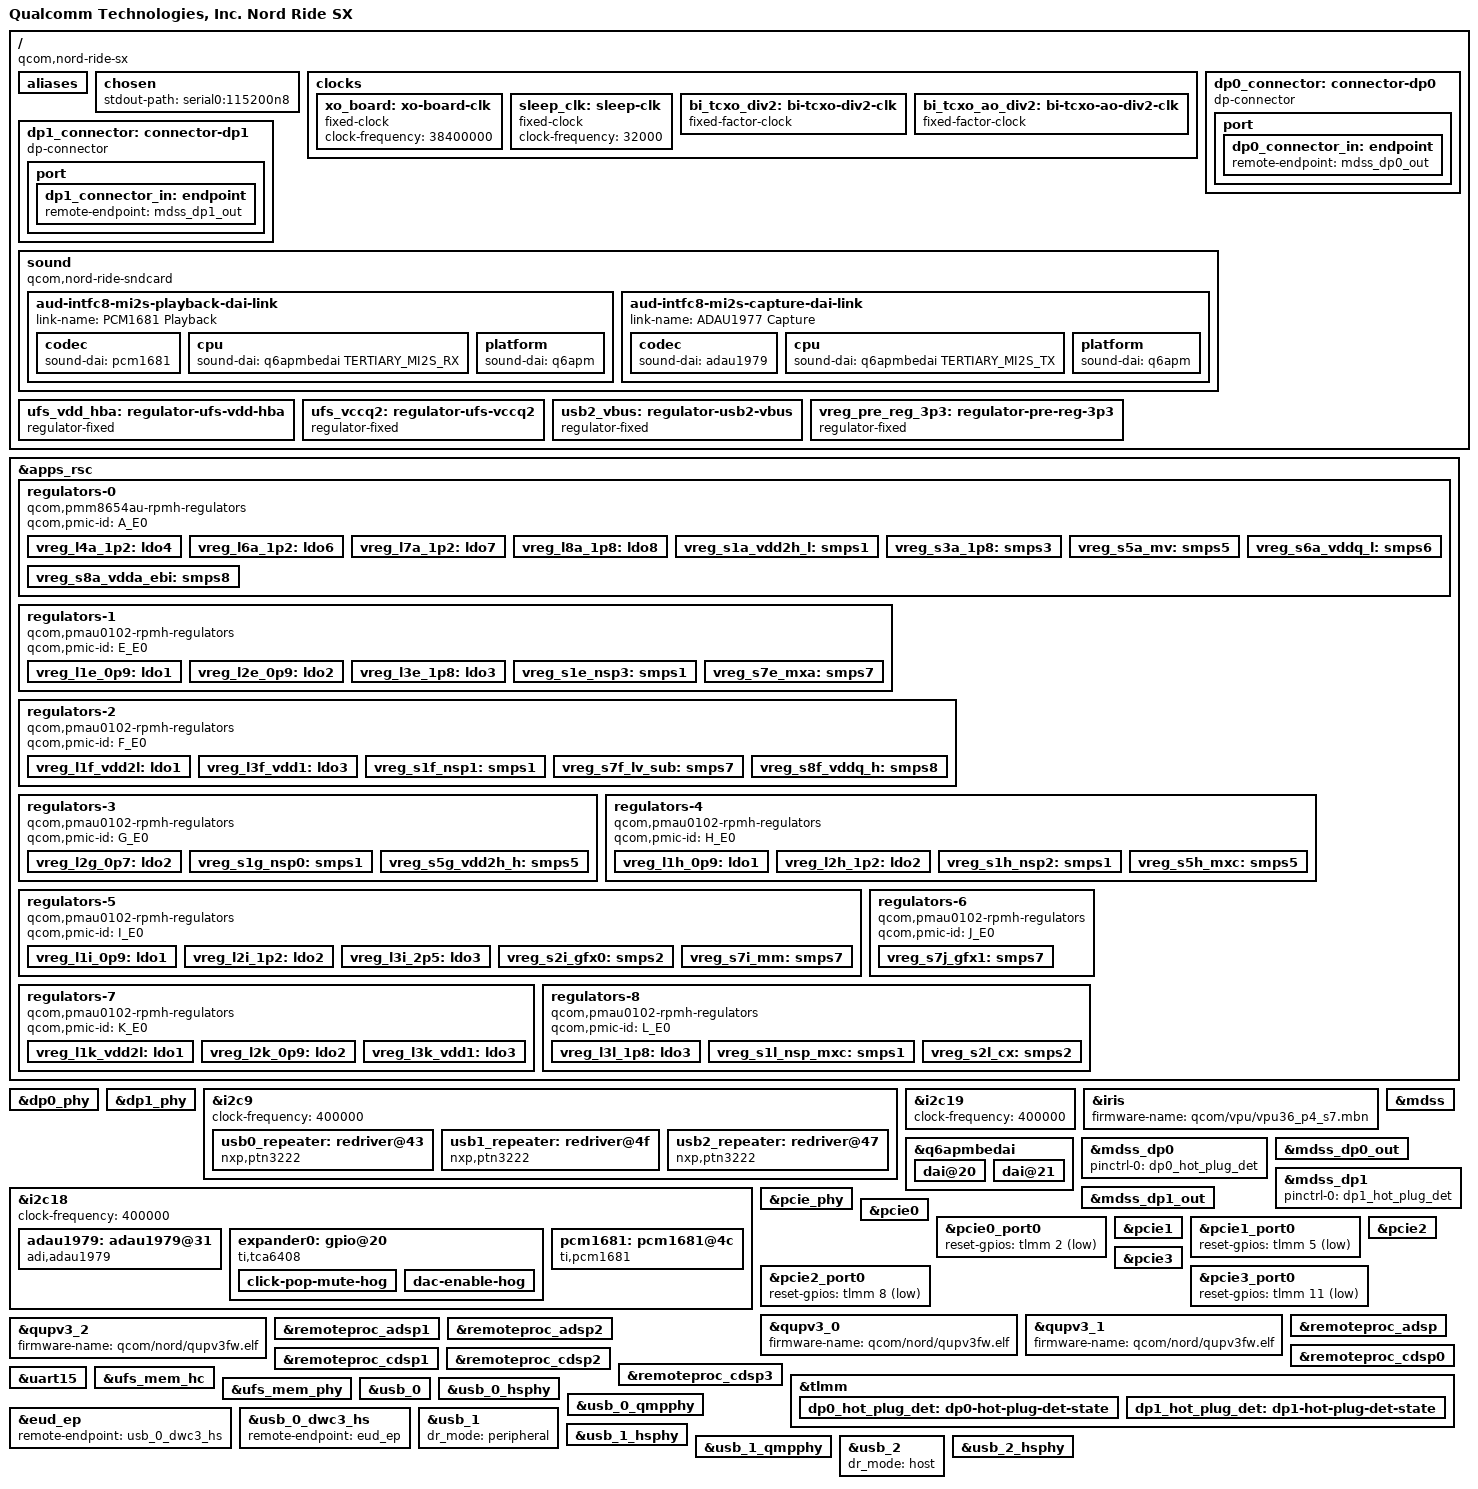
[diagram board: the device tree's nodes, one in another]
// SPDX-License-Identifier: BSD-3-Clause
/*
 * Copyright (c) Qualcomm Technologies, Inc. and/or its subsidiaries.
 */

/dts-v1/;

#include <dt-bindings/gpio/gpio.h>
#include <dt-bindings/sound/qcom,q6afe.h>
#include <dt-bindings/regulator/qcom,rpmh-regulator.h>

#include "nord-embedded.dtsi"

/ {
	model = "Qualcomm Technologies, Inc. Nord Ride SX";
	compatible = "qcom,nord-ride-sx", "qcom,nord";

	aliases {
		serial0 = &uart15;
		serial1 = &uart17;
	};

	chosen {
		stdout-path = "serial0:115200n8";
	};

	clocks {
		xo_board: xo-board-clk {
			compatible = "fixed-clock";
			clock-frequency = <38400000>;
			#clock-cells = <0>;
		};

		sleep_clk: sleep-clk {
			compatible = "fixed-clock";
			clock-frequency = <32000>;
			#clock-cells = <0>;
		};

		bi_tcxo_div2: bi-tcxo-div2-clk {
			compatible = "fixed-factor-clock";
			#clock-cells = <0>;
			clocks = <&rpmhcc RPMH_CXO_CLK>;
			clock-mult = <1>;
			clock-div = <2>;
		};

		bi_tcxo_ao_div2: bi-tcxo-ao-div2-clk {
			compatible = "fixed-factor-clock";
			#clock-cells = <0>;
			clocks = <&rpmhcc RPMH_CXO_CLK_A>;
			clock-mult = <1>;
			clock-div = <2>;
		};
	};

	dp0_connector: connector-dp0 {
		compatible = "dp-connector";
		label = "eDP0";
		type = "full-size";

		port {
			dp0_connector_in: endpoint {
				remote-endpoint = <&mdss_dp0_out>;
			};
		};
	};

	dp1_connector: connector-dp1 {
		compatible = "dp-connector";
		label = "eDP1";
		type = "full-size";

		port {
			dp1_connector_in: endpoint {
				remote-endpoint = <&mdss_dp1_out>;
			};
		};
	};

	sound {
		compatible = "qcom,nord-ride-sndcard";
		model = "NORD-RIDE-SX";

		pinctrl-0 = <&aud_intfc8_mi2s_active>, <&aud_mclk0_mira_active>;
		pinctrl-names = "default";

		aud-intfc8-mi2s-playback-dai-link {
			link-name = "PCM1681 Playback";

			codec {
				sound-dai = <&pcm1681>;
			};

			cpu {
				sound-dai = <&q6apmbedai TERTIARY_MI2S_RX>;
			};

			platform {
				sound-dai = <&q6apm>;
			};
		};

		aud-intfc8-mi2s-capture-dai-link {
			link-name = "ADAU1977 Capture";

			codec {
				sound-dai = <&adau1979>;
			};

			cpu {
				sound-dai = <&q6apmbedai TERTIARY_MI2S_TX>;
			};

			platform {
				sound-dai = <&q6apm>;
			};
		};
	};

	ufs_vdd_hba: regulator-ufs-vdd-hba {
		compatible = "regulator-fixed";
		regulator-name = "ufs_vdd_hba";
		regulator-min-microvolt = <1200000>;
		regulator-max-microvolt = <1200000>;
		regulator-always-on;
	};

	ufs_vccq2: regulator-ufs-vccq2 {
		compatible = "regulator-fixed";
		regulator-name = "ufs_vccq2";
		regulator-min-microvolt = <1800000>;
		regulator-max-microvolt = <1800000>;
		regulator-always-on;
	};

	usb2_vbus: regulator-usb2-vbus {
		compatible = "regulator-fixed";
		regulator-name = "usb2_vbus";
		regulator-min-microvolt = <5000000>;
		regulator-max-microvolt = <5000000>;
		gpio = <&pmau0102_h_gpios 3 GPIO_ACTIVE_HIGH>;
		enable-active-high;
		regulator-always-on;
	};

	vreg_pre_reg_3p3: regulator-pre-reg-3p3 {
		compatible = "regulator-fixed";
		regulator-name = "vreg_pre_reg_3p3";
		regulator-min-microvolt = <3300000>;
		regulator-max-microvolt = <3300000>;
		regulator-always-on;
	};
};

&apps_rsc {
	regulators-0 {
		compatible = "qcom,pmm8654au-rpmh-regulators";
		qcom,pmic-id = "A_E0";

		vreg_l4a_1p2: ldo4 {
			regulator-name = "vreg_l4a_1p2";
			regulator-min-microvolt = <1200000>;
			regulator-max-microvolt = <1200000>;
			regulator-initial-mode = <RPMH_REGULATOR_MODE_HPM>;
			regulator-allow-set-load;
			regulator-allowed-modes = <RPMH_REGULATOR_MODE_LPM
						   RPMH_REGULATOR_MODE_HPM>;
		};

		vreg_l6a_1p2: ldo6 {
			regulator-name = "vreg_l6a_1p2";
			regulator-min-microvolt = <1200000>;
			regulator-max-microvolt = <1200000>;
			regulator-initial-mode = <RPMH_REGULATOR_MODE_HPM>;
			regulator-allow-set-load;
			regulator-allowed-modes = <RPMH_REGULATOR_MODE_LPM
						   RPMH_REGULATOR_MODE_HPM>;
		};

		vreg_l7a_1p2: ldo7 {
			regulator-name = "vreg_l7a_1p2";
			regulator-min-microvolt = <1200000>;
			regulator-max-microvolt = <1200000>;
			regulator-initial-mode = <RPMH_REGULATOR_MODE_HPM>;
			regulator-always-on;
			regulator-boot-on;
			regulator-allow-set-load;
			regulator-allowed-modes = <RPMH_REGULATOR_MODE_LPM
						   RPMH_REGULATOR_MODE_HPM>;
		};

		vreg_l8a_1p8: ldo8 {
			regulator-name = "vreg_l8a_1p8";
			regulator-min-microvolt = <1800000>;
			regulator-max-microvolt = <1800000>;
			regulator-initial-mode = <RPMH_REGULATOR_MODE_HPM>;
			regulator-always-on;
			regulator-boot-on;
			regulator-allow-set-load;
			regulator-allowed-modes = <RPMH_REGULATOR_MODE_LPM
						   RPMH_REGULATOR_MODE_HPM>;
		};

		vreg_s1a_vdd2h_l: smps1 {
			regulator-name = "vreg_s1a_vdd2h_l";
			regulator-min-microvolt = <900000>;
			regulator-max-microvolt = <1100000>;
			regulator-initial-mode = <RPMH_REGULATOR_MODE_HPM>;
			regulator-always-on;
			regulator-boot-on;
		};

		vreg_s3a_1p8: smps3 {
			regulator-name = "vreg_s3a_1p8";
			regulator-min-microvolt = <1800000>;
			regulator-max-microvolt = <1800000>;
			regulator-initial-mode = <RPMH_REGULATOR_MODE_HPM>;
			regulator-always-on;
			regulator-boot-on;
		};

		vreg_s5a_mv: smps5 {
			regulator-name = "vreg_s5a_mv";
			regulator-min-microvolt = <1328000>;
			regulator-max-microvolt = <1370000>;
			regulator-initial-mode = <RPMH_REGULATOR_MODE_HPM>;
			regulator-always-on;
			regulator-boot-on;
		};

		vreg_s6a_vddq_l: smps6 {
			regulator-name = "vreg_s6a_vddq_l";
			regulator-min-microvolt = <500000>;
			regulator-max-microvolt = <570000>;
			regulator-initial-mode = <RPMH_REGULATOR_MODE_HPM>;
			regulator-allow-set-load;
			regulator-allowed-modes = <RPMH_REGULATOR_MODE_LPM
						   RPMH_REGULATOR_MODE_HPM>;
		};

		vreg_s8a_vdda_ebi: smps8 {
			regulator-name = "vreg_s8a_vdda_ebi";
			regulator-min-microvolt = <300000>;
			regulator-max-microvolt = <1200000>;
			regulator-initial-mode = <RPMH_REGULATOR_MODE_HPM>;
			regulator-always-on;
			regulator-boot-on;
		};
	};

	regulators-1 {
		compatible = "qcom,pmau0102-rpmh-regulators";
		qcom,pmic-id = "E_E0";

		vreg_l1e_0p9: ldo1 {
			regulator-name = "vreg_l1e_0p9";
			regulator-min-microvolt = <936000>;
			regulator-max-microvolt = <936000>;
			regulator-initial-mode = <RPMH_REGULATOR_MODE_HPM>;
			regulator-allow-set-load;
			regulator-allowed-modes = <RPMH_REGULATOR_MODE_LPM
						   RPMH_REGULATOR_MODE_HPM>;
		};

		vreg_l2e_0p9: ldo2 {
			regulator-name = "vreg_l2e_0p9";
			regulator-min-microvolt = <936000>;
			regulator-max-microvolt = <936000>;
			regulator-initial-mode = <RPMH_REGULATOR_MODE_HPM>;
			regulator-allow-set-load;
			regulator-allowed-modes = <RPMH_REGULATOR_MODE_LPM
						   RPMH_REGULATOR_MODE_HPM>;
		};

		vreg_l3e_1p8: ldo3 {
			regulator-name = "vreg_l3e_1p8";
			regulator-min-microvolt = <1800000>;
			regulator-max-microvolt = <1800000>;
			regulator-initial-mode = <RPMH_REGULATOR_MODE_HPM>;
			regulator-always-on;
			regulator-boot-on;
			regulator-allow-set-load;
			regulator-allowed-modes = <RPMH_REGULATOR_MODE_LPM
						   RPMH_REGULATOR_MODE_HPM>;
		};

		vreg_s1e_nsp3: smps1 {
			regulator-name = "vreg_s1e_nsp3";
			regulator-min-microvolt = <300000>;
			regulator-max-microvolt = <1200000>;
			regulator-initial-mode = <RPMH_REGULATOR_MODE_HPM>;
			regulator-allow-set-load;
			regulator-allowed-modes = <RPMH_REGULATOR_MODE_LPM
						   RPMH_REGULATOR_MODE_HPM>;
		};

		vreg_s7e_mxa: smps7 {
			regulator-name = "vreg_s7e_mxa";
			regulator-min-microvolt = <300000>;
			regulator-max-microvolt = <1200000>;
			regulator-initial-mode = <RPMH_REGULATOR_MODE_HPM>;
			regulator-always-on;
			regulator-boot-on;
		};
	};

	regulators-2 {
		compatible = "qcom,pmau0102-rpmh-regulators";
		qcom,pmic-id = "F_E0";

		vreg_l1f_vdd2l: ldo1 {
			regulator-name = "vreg_l1f_vdd2l";
			regulator-min-microvolt = <904000>;
			regulator-max-microvolt = <904000>;
			regulator-initial-mode = <RPMH_REGULATOR_MODE_HPM>;
			regulator-always-on;
			regulator-boot-on;
			regulator-allow-set-load;
			regulator-allowed-modes = <RPMH_REGULATOR_MODE_LPM
						   RPMH_REGULATOR_MODE_HPM>;
		};

		vreg_l3f_vdd1: ldo3 {
			regulator-name = "vreg_l3f_vdd1";
			regulator-min-microvolt = <1800000>;
			regulator-max-microvolt = <1800000>;
			regulator-initial-mode = <RPMH_REGULATOR_MODE_HPM>;
			regulator-always-on;
			regulator-boot-on;
			regulator-allow-set-load;
			regulator-allowed-modes = <RPMH_REGULATOR_MODE_LPM
						   RPMH_REGULATOR_MODE_HPM>;
		};

		vreg_s1f_nsp1: smps1 {
			regulator-name = "vreg_s1f_nsp1";
			regulator-min-microvolt = <300000>;
			regulator-max-microvolt = <1200000>;
			regulator-initial-mode = <RPMH_REGULATOR_MODE_HPM>;
			regulator-allow-set-load;
			regulator-allowed-modes = <RPMH_REGULATOR_MODE_LPM
						   RPMH_REGULATOR_MODE_HPM>;
		};

		vreg_s7f_lv_sub: smps7 {
			regulator-name = "vreg_s7f_lv_sub";
			regulator-min-microvolt = <1036000>;
			regulator-max-microvolt = <1136000>;
			regulator-initial-mode = <RPMH_REGULATOR_MODE_HPM>;
			regulator-always-on;
			regulator-boot-on;
		};

		vreg_s8f_vddq_h: smps8 {
			regulator-name = "vreg_s8f_vddq_h";
			regulator-min-microvolt = <500000>;
			regulator-max-microvolt = <570000>;
			regulator-initial-mode = <RPMH_REGULATOR_MODE_HPM>;
			regulator-allow-set-load;
			regulator-allowed-modes = <RPMH_REGULATOR_MODE_LPM
						   RPMH_REGULATOR_MODE_HPM>;
		};
	};

	regulators-3 {
		compatible = "qcom,pmau0102-rpmh-regulators";
		qcom,pmic-id = "G_E0";

		vreg_l2g_0p7: ldo2 {
			regulator-name = "vreg_l2g_0p7";
			regulator-min-microvolt = <752000>;
			regulator-max-microvolt = <752000>;
			regulator-initial-mode = <RPMH_REGULATOR_MODE_HPM>;
			regulator-allow-set-load;
			regulator-allowed-modes = <RPMH_REGULATOR_MODE_LPM
						   RPMH_REGULATOR_MODE_HPM>;
		};

		vreg_s1g_nsp0: smps1 {
			regulator-name = "vreg_s1g_nsp0";
			regulator-min-microvolt = <300000>;
			regulator-max-microvolt = <1200000>;
			regulator-initial-mode = <RPMH_REGULATOR_MODE_HPM>;
			regulator-allow-set-load;
			regulator-allowed-modes = <RPMH_REGULATOR_MODE_LPM
						   RPMH_REGULATOR_MODE_HPM>;
		};

		vreg_s5g_vdd2h_h: smps5 {
			regulator-name = "vreg_s5g_vdd2h_h";
			regulator-min-microvolt = <1080000>;
			regulator-max-microvolt = <1150000>;
			regulator-initial-mode = <RPMH_REGULATOR_MODE_HPM>;
			regulator-always-on;
			regulator-boot-on;
		};
	};

	/* PMIC H - "UPMH" satellite (CD90-73961-1) - SID 0x7, Bus E0 */
	regulators-4 {
		compatible = "qcom,pmau0102-rpmh-regulators";
		qcom,pmic-id = "H_E0";

		vreg_l1h_0p9: ldo1 {
			regulator-name = "vreg_l1h_0p9";
			regulator-min-microvolt = <904000>;
			regulator-max-microvolt = <904000>;
			regulator-initial-mode = <RPMH_REGULATOR_MODE_HPM>;
			regulator-allow-set-load;
			regulator-allowed-modes = <RPMH_REGULATOR_MODE_LPM
						   RPMH_REGULATOR_MODE_HPM>;
		};

		vreg_l2h_1p2: ldo2 {
			regulator-name = "vreg_l2h_1p2";
			regulator-min-microvolt = <1200000>;
			regulator-max-microvolt = <1200000>;
			regulator-initial-mode = <RPMH_REGULATOR_MODE_HPM>;
			regulator-allow-set-load;
			regulator-allowed-modes = <RPMH_REGULATOR_MODE_LPM
						   RPMH_REGULATOR_MODE_HPM>;
		};

		vreg_s1h_nsp2: smps1 {
			regulator-name = "vreg_s1h_nsp2";
			regulator-min-microvolt = <300000>;
			regulator-max-microvolt = <1200000>;
			regulator-initial-mode = <RPMH_REGULATOR_MODE_HPM>;
			regulator-allow-set-load;
			regulator-allowed-modes = <RPMH_REGULATOR_MODE_LPM
						   RPMH_REGULATOR_MODE_HPM>;
		};

		vreg_s5h_mxc: smps5 {
			regulator-name = "vreg_s5h_mxc";
			regulator-min-microvolt = <300000>;
			regulator-max-microvolt = <1200000>;
			regulator-initial-mode = <RPMH_REGULATOR_MODE_HPM>;
			regulator-allow-set-load;
			regulator-allowed-modes = <RPMH_REGULATOR_MODE_LPM
						   RPMH_REGULATOR_MODE_HPM>;
		};
	};

	/* PMIC I - "UPMI" satellite (CD90-73961-1) - SID 0x8, Bus E0 */
	regulators-5 {
		compatible = "qcom,pmau0102-rpmh-regulators";
		qcom,pmic-id = "I_E0";

		vreg_l1i_0p9: ldo1 {
			regulator-name = "vreg_l1i_0p9";
			regulator-min-microvolt = <912000>;
			regulator-max-microvolt = <912000>;
			regulator-initial-mode = <RPMH_REGULATOR_MODE_HPM>;
			regulator-allow-set-load;
			regulator-allowed-modes = <RPMH_REGULATOR_MODE_LPM
						   RPMH_REGULATOR_MODE_HPM>;
		};

		vreg_l2i_1p2: ldo2 {
			regulator-name = "vreg_l2i_1p2";
			regulator-min-microvolt = <1200000>;
			regulator-max-microvolt = <1200000>;
			regulator-initial-mode = <RPMH_REGULATOR_MODE_HPM>;
			regulator-always-on;
			regulator-boot-on;
			regulator-allow-set-load;
			regulator-allowed-modes = <RPMH_REGULATOR_MODE_LPM
						   RPMH_REGULATOR_MODE_HPM>;
		};

		vreg_l3i_2p5: ldo3 {
			regulator-name = "vreg_l3i_2p5";
			regulator-min-microvolt = <2504000>;
			regulator-max-microvolt = <2504000>;
			regulator-initial-mode = <RPMH_REGULATOR_MODE_HPM>;
			regulator-allow-set-load;
			regulator-allowed-modes = <RPMH_REGULATOR_MODE_LPM
						   RPMH_REGULATOR_MODE_HPM>;
		};

		vreg_s2i_gfx0: smps2 {
			regulator-name = "vreg_s2i_gfx0";
			regulator-min-microvolt = <300000>;
			regulator-max-microvolt = <1200000>;
			regulator-initial-mode = <RPMH_REGULATOR_MODE_HPM>;
			regulator-allow-set-load;
			regulator-allowed-modes = <RPMH_REGULATOR_MODE_LPM
						   RPMH_REGULATOR_MODE_HPM>;
		};

		vreg_s7i_mm: smps7 {
			regulator-name = "vreg_s7i_mm";
			regulator-min-microvolt = <300000>;
			regulator-max-microvolt = <1200000>;
			regulator-initial-mode = <RPMH_REGULATOR_MODE_HPM>;
			regulator-allow-set-load;
			regulator-allowed-modes = <RPMH_REGULATOR_MODE_LPM
						   RPMH_REGULATOR_MODE_HPM>;
		};
	};

	/* PMIC J - "UPMJ" satellite (CD90-73961-1) - SID 0x9, Bus E0 */
	regulators-6 {
		compatible = "qcom,pmau0102-rpmh-regulators";
		qcom,pmic-id = "J_E0";

		vreg_s7j_gfx1: smps7 {
			regulator-name = "vreg_s7j_gfx1";
			regulator-min-microvolt = <300000>;
			regulator-max-microvolt = <1200000>;
			regulator-initial-mode = <RPMH_REGULATOR_MODE_HPM>;
			regulator-allow-set-load;
			regulator-allowed-modes = <RPMH_REGULATOR_MODE_LPM
						   RPMH_REGULATOR_MODE_HPM>;
		};
	};

	/* PMIC K - "UPMK" satellite (CD90-73961-1) - SID 0xA, Bus E0 */
	regulators-7 {
		compatible = "qcom,pmau0102-rpmh-regulators";
		qcom,pmic-id = "K_E0";

		vreg_l1k_vdd2l: ldo1 {
			regulator-name = "vreg_l1k_vdd2l";
			regulator-min-microvolt = <904000>;
			regulator-max-microvolt = <904000>;
			regulator-initial-mode = <RPMH_REGULATOR_MODE_HPM>;
			regulator-always-on;
			regulator-boot-on;
			regulator-allow-set-load;
			regulator-allowed-modes = <RPMH_REGULATOR_MODE_LPM
						   RPMH_REGULATOR_MODE_HPM>;
		};

		vreg_l2k_0p9: ldo2 {
			regulator-name = "vreg_l2k_0p9";
			regulator-min-microvolt = <880000>;
			regulator-max-microvolt = <880000>;
			regulator-initial-mode = <RPMH_REGULATOR_MODE_HPM>;
			regulator-allow-set-load;
			regulator-allowed-modes = <RPMH_REGULATOR_MODE_LPM
						   RPMH_REGULATOR_MODE_HPM>;
		};

		vreg_l3k_vdd1: ldo3 {
			regulator-name = "vreg_l3k_vdd1";
			regulator-min-microvolt = <1800000>;
			regulator-max-microvolt = <1800000>;
			regulator-initial-mode = <RPMH_REGULATOR_MODE_HPM>;
			regulator-always-on;
			regulator-boot-on;
			regulator-allow-set-load;
			regulator-allowed-modes = <RPMH_REGULATOR_MODE_LPM
						   RPMH_REGULATOR_MODE_HPM>;
		};
	};

	/* PMIC L - "UPML" satellite (CD90-73961-1) - SID 0xB, Bus E0 */
	regulators-8 {
		compatible = "qcom,pmau0102-rpmh-regulators";
		qcom,pmic-id = "L_E0";

		vreg_l3l_1p8: ldo3 {
			regulator-name = "vreg_l3l_1p8";
			regulator-min-microvolt = <1800000>;
			regulator-max-microvolt = <1800000>;
			regulator-initial-mode = <RPMH_REGULATOR_MODE_HPM>;
			regulator-allow-set-load;
			regulator-allowed-modes = <RPMH_REGULATOR_MODE_LPM
						   RPMH_REGULATOR_MODE_HPM>;
		};

		vreg_s1l_nsp_mxc: smps1 {
			regulator-name = "vreg_s1l_nsp_mxc";
			regulator-min-microvolt = <300000>;
			regulator-max-microvolt = <1200000>;
			regulator-initial-mode = <RPMH_REGULATOR_MODE_HPM>;
			regulator-allow-set-load;
			regulator-allowed-modes = <RPMH_REGULATOR_MODE_LPM
						   RPMH_REGULATOR_MODE_HPM>;
		};

		vreg_s2l_cx: smps2 {
			regulator-name = "vreg_s2l_cx";
			regulator-min-microvolt = <300000>;
			regulator-max-microvolt = <1200000>;
			regulator-initial-mode = <RPMH_REGULATOR_MODE_HPM>;
			regulator-allow-set-load;
			regulator-allowed-modes = <RPMH_REGULATOR_MODE_LPM
						   RPMH_REGULATOR_MODE_HPM>;
		};
	};
};

&dp0_phy {
	vdda-phy-supply = <&vreg_l2h_1p2>;
	vdda-pll-supply = <&vreg_l1h_0p9>;

	status = "okay";
};

&dp1_phy {
	vdda-phy-supply = <&vreg_l2h_1p2>;
	vdda-pll-supply = <&vreg_l1h_0p9>;

	status = "okay";
};

&i2c9 {
	clock-frequency = <400000>;

	status = "okay";

	usb0_repeater: redriver@43 {
		compatible = "nxp,ptn3222";
		reg = <0x43>;
		#phy-cells = <0>;

		vdd1v8-supply = <&vreg_l3l_1p8>;

		reset-gpios = <&pmau0102_i_gpios 9 GPIO_ACTIVE_LOW>;
	};

	usb1_repeater: redriver@4f {
		compatible = "nxp,ptn3222";
		reg = <0x4f>;
		#phy-cells = <0>;

		vdd1v8-supply = <&vreg_l3l_1p8>;

		reset-gpios = <&pmau0102_i_gpios 10 GPIO_ACTIVE_LOW>;
	};

	usb2_repeater: redriver@47 {
		compatible = "nxp,ptn3222";
		reg = <0x47>;
		#phy-cells = <0>;

		vdd1v8-supply = <&vreg_l3l_1p8>;

		reset-gpios = <&pmau0102_l_gpios 3 GPIO_ACTIVE_LOW>;
	};
};

&i2c18 {
	clock-frequency = <400000>;

	status = "okay";

	/* ADI ADAU1979 - 4-channel 24-bit ADC */
	adau1979: adau1979@31 {
		compatible = "adi,adau1979";
		reg = <0x31>;

		AVDD-supply  = <&vreg_pre_reg_3p3>;
		IOVDD-supply = <&vreg_pre_reg_3p3>;
		#sound-dai-cells = <0>;
	};

	expander0: gpio@20 {
		compatible = "ti,tca6408";
		reg = <0x20>;
		#gpio-cells = <2>;
		gpio-controller;
		#interrupt-cells = <2>;
		interrupt-controller;
		interrupts-extended = <&pmau0102_l_gpios 6 GPIO_ACTIVE_LOW>;
		reset-gpios = <&pmau0102_l_gpios 5 GPIO_ACTIVE_LOW>;

		click-pop-mute-hog {
			gpio-hog;
			gpios = <5 GPIO_ACTIVE_HIGH>;
			output-high;
			line-name = "click-pop-mute-n";
		};

		dac-enable-hog {
			gpio-hog;
			gpios = <6 GPIO_ACTIVE_HIGH>;
			output-high;
			line-name = "dac_enable";
		};
	};

	/* PCM1681 DAC */
	pcm1681: pcm1681@4c {
		compatible = "ti,pcm1681";
		reg = <0x4c>;

		clocks = <&q6prmcc LPASS_CLK_ID_MCLK_1 LPASS_CLK_ATTRIBUTE_COUPLE_NO>;
		clock-names = "sclk";
		assigned-clocks = <&q6prmcc LPASS_CLK_ID_MCLK_1 LPASS_CLK_ATTRIBUTE_COUPLE_NO>;
		assigned-clock-rates = <12288000>;

		#sound-dai-cells = <0>;
	};
};

&i2c19 {
	clock-frequency = <400000>;

	status = "okay";
};

&iris {
	firmware-name = "qcom/vpu/vpu36_p4_s7.mbn";

	status = "okay";
};

&q6apmbedai {
	#address-cells = <1>;
	#size-cells = <0>;

	dai@20 {
		reg = <TERTIARY_MI2S_RX>;
		clocks = <&q6prmcc LPASS_CLK_ID_AUD_INTF8_IBIT LPASS_CLK_ATTRIBUTE_COUPLE_NO>;
		clock-names = "bclk";
	};

	dai@21 {
		reg = <TERTIARY_MI2S_TX>;
		clocks = <&q6prmcc LPASS_CLK_ID_AUD_INTF8_IBIT LPASS_CLK_ATTRIBUTE_COUPLE_NO>;
		clock-names = "bclk";
	};
};

&mdss {
	status = "okay";
};

&mdss_dp0 {
	pinctrl-0 = <&dp0_hot_plug_det>;
	pinctrl-names = "default";

	status = "okay";
};

&mdss_dp0_out {
	data-lanes = <0 1 2 3>;
	link-frequencies = /bits/ 64 <1620000000 2700000000 5400000000 8100000000>;
	remote-endpoint = <&dp0_connector_in>;
};

&mdss_dp1 {
	pinctrl-0 = <&dp1_hot_plug_det>;
	pinctrl-names = "default";

	status = "okay";
};

&mdss_dp1_out {
	data-lanes = <0 1 2 3>;
	link-frequencies = /bits/ 64 <1620000000 2700000000 5400000000 8100000000>;
	remote-endpoint = <&dp1_connector_in>;
};

&pcie_phy {
	vdda-phy-a-supply = <&vreg_l6a_1p2>;
	vdda-phy-b-supply = <&vreg_l4a_1p2>;
	vdda-phy-c-supply = <&vreg_l4a_1p2>;
	vdda-phy-d-supply = <&vreg_l4a_1p2>;
	vdda-pll-a-supply = <&vreg_l1e_0p9>;
	vdda-pll-b-supply = <&vreg_l1e_0p9>;
	vdda-pll-c-supply = <&vreg_l1e_0p9>;
	vdda-pll-d-supply = <&vreg_l1e_0p9>;
	vdda-qref-a-supply = <&vreg_l2e_0p9>;
	vdda-qref-b-supply = <&vreg_l2e_0p9>;
	vdda-qref-c-supply = <&vreg_l2e_0p9>;
	vdda-qref-d-supply = <&vreg_l2e_0p9>;

	status = "okay";
};

&pcie0 {
	status = "okay";
};

&pcie0_port0 {
	reset-gpios = <&tlmm 2 GPIO_ACTIVE_LOW>;
};

&pcie1 {
	status = "okay";
};

&pcie1_port0 {
	reset-gpios = <&tlmm 5 GPIO_ACTIVE_LOW>;
};

&pcie2 {
	status = "okay";
};

&pcie2_port0 {
	reset-gpios = <&tlmm 8 GPIO_ACTIVE_LOW>;
};

&pcie3 {
	status = "okay";
};

&pcie3_port0 {
	reset-gpios = <&tlmm 11 GPIO_ACTIVE_LOW>;
};

&qupv3_0 {
	firmware-name = "qcom/nord/qupv3fw.elf";

	status = "okay";
};

&qupv3_1 {
	firmware-name = "qcom/nord/qupv3fw.elf";

	status = "okay";
};

&qupv3_2 {
	firmware-name = "qcom/nord/qupv3fw.elf";

	status = "okay";
};

&remoteproc_adsp {
	firmware-name = "qcom/nord/adsp.mbn",
			"qcom/nord/adsp_dtbs.elf";

	status = "okay";
};

&remoteproc_adsp1 {
	firmware-name = "qcom/nord/adsp1.mbn",
			"qcom/nord/adsp1_dtbs.elf";

	status = "okay";
};

&remoteproc_adsp2 {
	firmware-name = "qcom/nord/adsp2.mbn",
			"qcom/nord/adsp2_dtbs.elf";

	status = "okay";
};

&remoteproc_cdsp0 {
	firmware-name = "qcom/nord/cdsp.mbn",
			"qcom/nord/cdsp_dtbs.elf";

	status = "okay";
};

&remoteproc_cdsp1 {
	firmware-name = "qcom/nord/cdsp1.mbn",
			"qcom/nord/cdsp1_dtbs.elf";

	status = "okay";
};

&remoteproc_cdsp2 {
	firmware-name = "qcom/nord/cdsp2.mbn",
			"qcom/nord/cdsp2_dtbs.elf";

	status = "okay";
};

&remoteproc_cdsp3 {
	firmware-name = "qcom/nord/cdsp3.mbn",
			"qcom/nord/cdsp3_dtbs.elf";

	status = "okay";
};

&tlmm {
	dp0_hot_plug_det: dp0-hot-plug-det-state {
		pins = "gpio51";
		function = "edp0_hot";
		bias-disable;
	};

	dp1_hot_plug_det: dp1-hot-plug-det-state {
		pins = "gpio52";
		function = "edp1_hot";
		bias-disable;
	};
};

&uart15 {
	status = "okay";
};

&ufs_mem_hc {
	reset-gpios = <&tlmm 181 GPIO_ACTIVE_LOW>;

	vcc-supply = <&vreg_l3i_2p5>;
	vcc-max-microamp = <1300000>;
	vccq-supply = <&vreg_l2i_1p2>;
	vccq-max-microamp = <1200000>;
	vccq2-supply = <&ufs_vccq2>;
	vdd-hba-supply = <&ufs_vdd_hba>;

	status = "okay";
};

&ufs_mem_phy {
	vdda-phy-supply = <&vreg_l1i_0p9>;
	vdda-pll-supply = <&vreg_l2h_1p2>;

	status = "okay";
};

&usb_0 {
	dr_mode = "otg";
	usb-role-switch;

	status = "okay";
};

&usb_0_hsphy {
	vdd-supply = <&vreg_l1e_0p9>;
	vdda12-supply = <&vreg_l2i_1p2>;

	phys = <&usb0_repeater>;

	status = "okay";
};

&usb_0_qmpphy {
	vdda-phy-supply = <&vreg_l1h_0p9>;
	vdda-pll-supply = <&vreg_l2h_1p2>;

	status = "okay";
};

&eud_ep {
	remote-endpoint = <&usb_0_dwc3_hs>;
};

&usb_0_dwc3_hs {
	remote-endpoint = <&eud_ep>;
};

&usb_1 {
	dr_mode = "peripheral";

	status = "okay";
};

&usb_1_hsphy {
	vdd-supply = <&vreg_l1e_0p9>;
	vdda12-supply = <&vreg_l2i_1p2>;

	phys = <&usb1_repeater>;

	status = "okay";
};

&usb_1_qmpphy {
	vdda-phy-supply = <&vreg_l1h_0p9>;
	vdda-pll-supply = <&vreg_l2h_1p2>;

	status = "okay";
};

&usb_2 {
	dr_mode = "host";

	status = "okay";
};

&usb_2_hsphy {
	vdd-supply = <&vreg_l1e_0p9>;
	vdda12-supply = <&vreg_l2i_1p2>;

	phys = <&usb2_repeater>;

	status = "okay";
};
